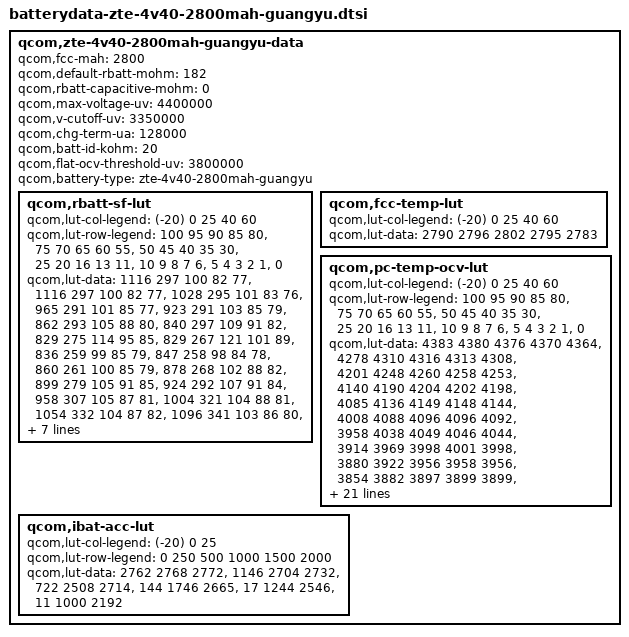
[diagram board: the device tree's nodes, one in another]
/* Copyright (c) 2014, The Linux Foundation. All rights reserved.
 *
 * This program is free software; you can redistribute it and/or modify
 * it under the terms of the GNU General Public License version 2 and
 * only version 2 as published by the Free Software Foundation.
 *
 * This program is distributed in the hope that it will be useful,
 * but WITHOUT ANY WARRANTY; without even the implied warranty of
 * MERCHANTABILITY or FITNESS FOR A PARTICULAR PURPOSE.  See the
 * GNU General Public License for more details.
 */
 qcom,zte-4v40-2800mah-guangyu-data {
	qcom,fcc-mah = <2800>;
	qcom,default-rbatt-mohm = <182>;
	qcom,rbatt-capacitive-mohm = <0>;
	qcom,max-voltage-uv = <4400000>;
	qcom,v-cutoff-uv = <3350000>;
	qcom,chg-term-ua = <128000>;
	qcom,batt-id-kohm = <20>;
	qcom,flat-ocv-threshold-uv = <3800000>;
	qcom,battery-type = "zte-4v40-2800mah-guangyu";
 
	qcom,rbatt-sf-lut {
		qcom,lut-col-legend = <(-20) 0 25 40 60>;
		qcom,lut-row-legend = <100 95 90 85 80>,
				<75 70 65 60 55>,
				<50 45 40 35 30>,
				<25 20 16 13 11>,
				<10 9 8 7 6>,
				<5 4 3 2 1>,
				<0>;
		qcom,lut-data = <1116 297 100 82 77>,
				<1116 297 100 82 77>,
				<1028 295 101 83 76>,
				<965 291 101 85 77>,
				<923 291 103 85 79>,
				<862 293 105 88 80>,
				<840 297 109 91 82>,
				<829 275 114 95 85>,
				<829 267 121 101 89>,
				<836 259 99 85 79>,
				<847 258 98 84 78>,
				<860 261 100 85 79>,
				<878 268 102 88 82>,
				<899 279 105 91 85>,
				<924 292 107 91 84>,
				<958 307 105 87 81>,
				<1004 321 104 88 81>,
				<1054 332 104 87 82>,
				<1096 341 103 86 80>,
				<1125 353 103 87 81>,
				<1123 355 105 88 82>,
				<1134 363 107 90 84>,
				<1160 374 110 91 86>,
				<1190 388 113 94 89>,
				<1216 392 116 97 90>,
				<1254 723 114 93 87>,
				<1366 1289 111 91 84>,
				<1527 1562 113 92 86>,
				<1938 1964 118 96 91>,
				<2832 2815 142 119 117>,
				<68513 50775 4435 5585 3088>;
	};

	qcom,fcc-temp-lut {
		qcom,lut-col-legend = <(-20) 0 25 40 60>;
		qcom,lut-data = <2790 2796 2802 2795 2783>;
	};

	qcom,pc-temp-ocv-lut {
		qcom,lut-col-legend = <(-20) 0 25 40 60>;
		qcom,lut-row-legend = <100 95 90 85 80>,
				<75 70 65 60 55>,
				<50 45 40 35 30>,
				<25 20 16 13 11>,
				<10 9 8 7 6>,
				<5 4 3 2 1>,
				<0>;
		qcom,lut-data = <4383 4380 4376 4370 4364>,
				<4278 4310 4316 4313 4308>,
				<4201 4248 4260 4258 4253>,
				<4140 4190 4204 4202 4198>,
				<4085 4136 4149 4148 4144>,
				<4008 4088 4096 4096 4092>,
				<3958 4038 4049 4046 4044>,
				<3914 3969 3998 4001 3998>,
				<3880 3922 3956 3958 3956>,
				<3854 3882 3897 3899 3899>,
				<3832 3850 3863 3864 3864>,
				<3814 3825 3836 3838 3838>,
				<3796 3806 3814 3816 3815>,
				<3780 3790 3795 3797 3796>,
				<3764 3778 3778 3778 3772>,
				<3748 3765 3760 3753 3742>,
				<3732 3746 3740 3732 3718>,
				<3719 3724 3717 3709 3695>,
				<3706 3706 3695 3687 3676>,
				<3696 3697 3689 3682 3670>,
				<3690 3694 3688 3680 3668>,
				<3684 3692 3686 3680 3668>,
				<3675 3689 3685 3678 3665>,
				<3665 3686 3682 3675 3662>,
				<3650 3682 3676 3668 3651>,
				<3628 3668 3656 3646 3624>,
				<3595 3627 3612 3603 3580>,
				<3546 3572 3552 3543 3519>,
				<3468 3490 3470 3462 3436>,
				<3338 3359 3348 3342 3306>,
				<3000 3024 3072 3000 3000>;
	};

	       /* cutof_mv 3350 */
		qcom,ibat-acc-lut {
		qcom,lut-col-legend = <(-20) 0 25>;
		qcom,lut-row-legend = <0 250 500 1000 1500 2000>;
		qcom,lut-data = <2762 2768 2772>,
					   <1146 2704 2732>,
					   <722 2508 2714>,
				       <144 1746 2665>,
					   <17 1244 2546>,
					   <11 1000 2192>;
	};

};
